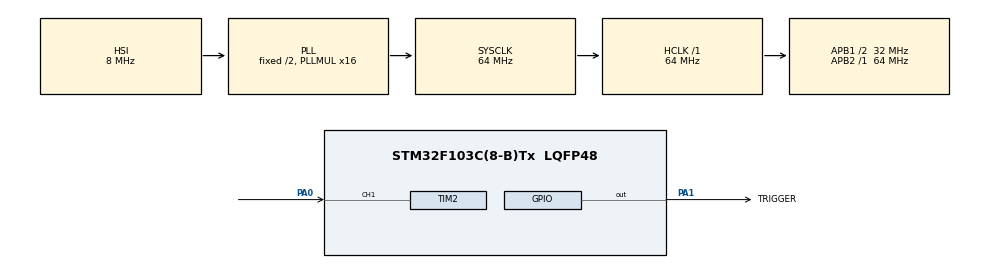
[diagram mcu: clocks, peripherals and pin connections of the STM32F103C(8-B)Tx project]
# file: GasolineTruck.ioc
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Mcu.Family=STM32F1
Mcu.Name=STM32F103C(8-B)Tx
Mcu.Package=LQFP48
NVIC.PriorityGroup=NVIC_PRIORITYGROUP_4
NVIC.TIM2_IRQn=true\:0\:0\:false\:false\:true\:true\:true
PA0-WKUP.Signal=S_TIM2_CH1_ETR
PA1.GPIO_Label=TRIGGER
PA1.Signal=GPIO_Output
PA13.Mode=Serial_Wire
PA13.Signal=SYS_JTMS-SWDIO
PA14.Mode=Serial_Wire
PA14.Signal=SYS_JTCK-SWCLK
ProjectManager.HeapSize=0x200
ProjectManager.StackSize=0x400
ProjectManager.TargetToolchain=STM32CubeIDE
RCC.AHBFreq_Value=64000000
RCC.APB1CLKDivider=RCC_HCLK_DIV2
RCC.APB1Freq_Value=32000000
RCC.APB1TimFreq_Value=64000000
RCC.APB2Freq_Value=64000000
RCC.APB2TimFreq_Value=64000000
RCC.HCLKFreq_Value=64000000
RCC.PLLMUL=RCC_PLL_MUL16
RCC.SYSCLKFreq_VALUE=64000000
RCC.SYSCLKSource=RCC_SYSCLKSOURCE_PLLCLK
RCC.USBFreq_Value=64000000
SH.S_TIM2_CH1_ETR.0=TIM2_CH1,Input_Capture1_from_TI1
TIM2.Channel-Input_Capture1_from_TI1=TIM_CHANNEL_1
TIM2.Period=0xffff-1
TIM2.Prescaler=64-1
VP_TIM2_VS_ClockSourceINT.Mode=Internal
board=custom

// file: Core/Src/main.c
/* USER CODE BEGIN Header */
/**
  ******************************************************************************
  * @file           : main.c
  * @brief          : Main program body
  ******************************************************************************
  * @attention
  *
  * <h2><center>&copy; Copyright (c) 2021 STMicroelectronics.
  * All rights reserved.</center></h2>
  *
  * This software component is licensed by ST under BSD 3-Clause license,
  * the "License"; You may not use this file except in compliance with the
  * License. You may obtain a copy of the License at:
  *                        opensource.org/licenses/BSD-3-Clause
  *
  ******************************************************************************
  */
/* USER CODE END Header */
#include "main.h"

/* USER CODE BEGIN Includes */
#include "stdbool.h"
/* USER CODE END Includes */

/* USER CODE BEGIN PD */
#define TRUCK_HEIGHT	50	//unit:	cm
/* USER CODE END PD */

TIM_HandleTypeDef htim2;

/* USER CODE BEGIN PV */
/*SENSOR*/
uint32_t IC_firstVal = 0;
uint32_t IC_secondVal = 0;
uint32_t IC_differenceVal = 0;
bool IC_isFirstCaptured = false;  // is the first value captured?
volatile uint16_t Ultrasonic_distanceVal  = 0;
volatile int16_t Gas_levelVal = 0;
/* USER CODE END PV */

void SystemClock_Config(void);
static void MX_GPIO_Init(void);
static void MX_TIM2_Init(void);
/* USER CODE BEGIN PFP */
/*SENSOR*/
void delay_us(uint32_t usTick);
void Ultrasonic_getDistance(void);
/* USER CODE END PFP */

/* USER CODE BEGIN 0 */
void HAL_TIM_IC_CaptureCallback(TIM_HandleTypeDef *htim)
{
	if (htim->Channel == HAL_TIM_ACTIVE_CHANNEL_1)
	{
		if (IC_isFirstCaptured == false)
		{
			IC_firstVal = HAL_TIM_ReadCapturedValue(htim, TIM_CHANNEL_1);
			IC_isFirstCaptured = true;
			__HAL_TIM_SET_CAPTUREPOLARITY(htim, TIM_CHANNEL_1, TIM_INPUTCHANNELPOLARITY_FALLING);
		}
		else
		{
			IC_secondVal = HAL_TIM_ReadCapturedValue(htim, TIM_CHANNEL_1);
			__HAL_TIM_SET_COUNTER(htim, 0);
			if (IC_secondVal > IC_firstVal)
			{
				IC_differenceVal = IC_secondVal-IC_firstVal;
			}
			else if (IC_firstVal > IC_secondVal)
			{
				IC_differenceVal = (0xffff - IC_firstVal) + IC_secondVal;
			}
			Ultrasonic_distanceVal = IC_differenceVal * 0.034/2; // range = high level time * velocity (340m/s) / 2
			IC_isFirstCaptured = false;
			__HAL_TIM_SET_CAPTUREPOLARITY(htim, TIM_CHANNEL_1, TIM_INPUTCHANNELPOLARITY_RISING);
			HAL_TIM_IC_Stop_IT(htim, TIM_IT_CC1);
		}
	}
}
/* USER CODE END 0 */

int main(void)
{

  /* MCU Configuration--------------------------------------------------------*/

  /* Reset of all peripherals, Initializes the Flash interface and the Systick. */
  HAL_Init();

  /* Configure the system clock */
  SystemClock_Config();

  /* Initialize all configured peripherals */
  MX_GPIO_Init();
  MX_TIM2_Init();
  /* USER CODE BEGIN 2 */
  HAL_TIM_IC_Start_IT(&htim2, TIM_CHANNEL_1);

  /* USER CODE END 2 */

  /* Infinite loop */
  /* USER CODE BEGIN WHILE */
  while (1)
  {
	  Ultrasonic_getDistance();
	  HAL_Delay(100);
	  Gas_levelVal = TRUCK_HEIGHT - Ultrasonic_distanceVal;
	  HAL_Delay(5000);
    /* USER CODE END WHILE */

  }
}

void SystemClock_Config(void)
{
  RCC_OscInitTypeDef RCC_OscInitStruct = {0};
  RCC_ClkInitTypeDef RCC_ClkInitStruct = {0};

  /** Initializes the RCC Oscillators according to the specified parameters
  * in the RCC_OscInitTypeDef structure.
  */
  RCC_OscInitStruct.OscillatorType = RCC_OSCILLATORTYPE_HSI;
  RCC_OscInitStruct.HSIState = RCC_HSI_ON;
  RCC_OscInitStruct.HSICalibrationValue = RCC_HSICALIBRATION_DEFAULT;
  RCC_OscInitStruct.PLL.PLLState = RCC_PLL_ON;
  RCC_OscInitStruct.PLL.PLLSource = RCC_PLLSOURCE_HSI_DIV2;
  RCC_OscInitStruct.PLL.PLLMUL = RCC_PLL_MUL16;
  if (HAL_RCC_OscConfig(&RCC_OscInitStruct) != HAL_OK)
  {
    Error_Handler();
  }
  /** Initializes the CPU, AHB and APB buses clocks
  */
  RCC_ClkInitStruct.ClockType = RCC_CLOCKTYPE_HCLK|RCC_CLOCKTYPE_SYSCLK
                              |RCC_CLOCKTYPE_PCLK1|RCC_CLOCKTYPE_PCLK2;
  RCC_ClkInitStruct.SYSCLKSource = RCC_SYSCLKSOURCE_PLLCLK;
  RCC_ClkInitStruct.AHBCLKDivider = RCC_SYSCLK_DIV1;
  RCC_ClkInitStruct.APB1CLKDivider = RCC_HCLK_DIV2;
  RCC_ClkInitStruct.APB2CLKDivider = RCC_HCLK_DIV1;

  if (HAL_RCC_ClockConfig(&RCC_ClkInitStruct, FLASH_LATENCY_2) != HAL_OK)
  {
    Error_Handler();
  }
}

static void MX_TIM2_Init(void)
{

  TIM_ClockConfigTypeDef sClockSourceConfig = {0};
  TIM_MasterConfigTypeDef sMasterConfig = {0};
  TIM_IC_InitTypeDef sConfigIC = {0};

  htim2.Instance = TIM2;
  htim2.Init.Prescaler = 64-1;
  htim2.Init.CounterMode = TIM_COUNTERMODE_UP;
  htim2.Init.Period = 0xffff-1;
  htim2.Init.ClockDivision = TIM_CLOCKDIVISION_DIV1;
  htim2.Init.AutoReloadPreload = TIM_AUTORELOAD_PRELOAD_DISABLE;
  if (HAL_TIM_Base_Init(&htim2) != HAL_OK)
  {
    Error_Handler();
  }
  sClockSourceConfig.ClockSource = TIM_CLOCKSOURCE_INTERNAL;
  if (HAL_TIM_ConfigClockSource(&htim2, &sClockSourceConfig) != HAL_OK)
  {
    Error_Handler();
  }
  if (HAL_TIM_IC_Init(&htim2) != HAL_OK)
  {
    Error_Handler();
  }
  sMasterConfig.MasterOutputTrigger = TIM_TRGO_RESET;
  sMasterConfig.MasterSlaveMode = TIM_MASTERSLAVEMODE_DISABLE;
  if (HAL_TIMEx_MasterConfigSynchronization(&htim2, &sMasterConfig) != HAL_OK)
  {
    Error_Handler();
  }
  sConfigIC.ICPolarity = TIM_INPUTCHANNELPOLARITY_RISING;
  sConfigIC.ICSelection = TIM_ICSELECTION_DIRECTTI;
  sConfigIC.ICPrescaler = TIM_ICPSC_DIV1;
  sConfigIC.ICFilter = 0;
  if (HAL_TIM_IC_ConfigChannel(&htim2, &sConfigIC, TIM_CHANNEL_1) != HAL_OK)
  {
    Error_Handler();
  }

}

static void MX_GPIO_Init(void)
{
  GPIO_InitTypeDef GPIO_InitStruct = {0};

  /* GPIO Ports Clock Enable */
  __HAL_RCC_GPIOA_CLK_ENABLE();

  /*Configure GPIO pin Output Level */
  HAL_GPIO_WritePin(TRIGGER_GPIO_Port, TRIGGER_Pin, GPIO_PIN_RESET);

  /*Configure GPIO pin : TRIGGER_Pin */
  GPIO_InitStruct.Pin = TRIGGER_Pin;
  GPIO_InitStruct.Mode = GPIO_MODE_OUTPUT_PP;
  GPIO_InitStruct.Pull = GPIO_NOPULL;
  GPIO_InitStruct.Speed = GPIO_SPEED_FREQ_LOW;
  HAL_GPIO_Init(TRIGGER_GPIO_Port, &GPIO_InitStruct);

}

/* USER CODE BEGIN 4 */
void delay_us(uint32_t usTick)
{
  __HAL_TIM_SET_COUNTER(&htim2, 0);
	while (__HAL_TIM_GET_COUNTER (&htim2) < usTick);
}

void Ultrasonic_getDistance(void)
{
	HAL_GPIO_WritePin(TRIGGER_GPIO_Port, TRIGGER_Pin, GPIO_PIN_RESET);  // pull the TRIG pin low
	delay_us(2);  // wait for 2 us
	HAL_GPIO_WritePin(TRIGGER_GPIO_Port, TRIGGER_Pin, GPIO_PIN_SET);  // pull the TRIG pin HIGH
	delay_us(10);  // wait for 10 us
	HAL_GPIO_WritePin(TRIGGER_GPIO_Port, TRIGGER_Pin, GPIO_PIN_RESET);  // pull the TRIG pin low
	HAL_TIM_IC_Start_IT(&htim2, TIM_IT_CC1);
}
/* USER CODE END 4 */

void Error_Handler(void)
{
}

/************************ (C) COPYRIGHT STMicroelectronics *****END OF FILE****/
